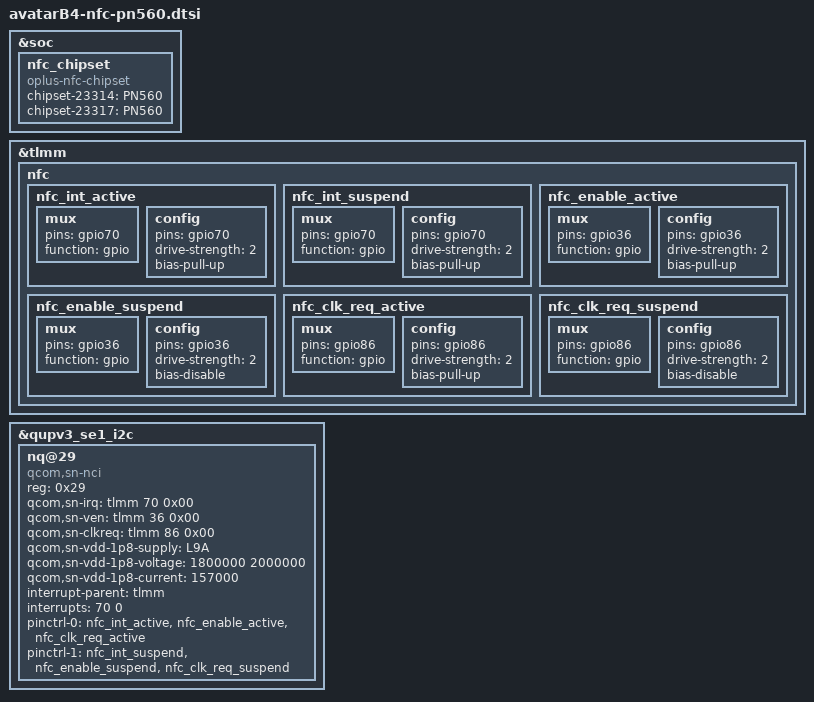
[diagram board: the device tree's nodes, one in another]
&soc {
	//add for nfc_chipset
	nfc_chipset {
		compatible = "oplus-nfc-chipset";
		chipset-23314 = "PN560";
		chipset-23317 = "PN560";
	};
};

&tlmm {
	nfc {
		nfc_int_active: nfc_int_active {
			/* active state */
			mux {
				/* GPIO 70 NFC Read Interrupt */
				pins = "gpio70";
				function = "gpio";
			};

			config {
				pins = "gpio70";
				drive-strength = <2>; /* 2 MA */
				bias-pull-up;
			};
		};

		nfc_int_suspend: nfc_int_suspend {
			/* sleep state */
			mux {
				/* GPIO 70 NFC Read Interrupt */
				pins = "gpio70";
				function = "gpio";
			};

			config {
				pins = "gpio70";
				drive-strength = <2>; /* 2 MA */
				bias-pull-up;
			};
		};

		nfc_enable_active: nfc_enable_active {
			/* active state */
			mux {
				/* 36: Enable */
				pins = "gpio36";
				function = "gpio";
			};

			config {
				pins = "gpio36";
				drive-strength = <2>; /* 2 MA */
				bias-pull-up;
			};
		};

		nfc_enable_suspend: nfc_enable_suspend {
			/* sleep state */
			mux {
				/* 36: Enable */
				pins = "gpio36";
				function = "gpio";
			};

			config {
				pins = "gpio36";
				drive-strength = <2>; /* 2 MA */
				bias-disable;
			};
		};

		nfc_clk_req_active: nfc_clk_req_active {
			/* active state */
			mux {
				/* GPIO 86: NFC CLOCK REQUEST */
				pins = "gpio86";
				function = "gpio";
			};

			config {
				pins = "gpio86";
				drive-strength = <2>; /* 2 MA */
				bias-pull-up;
			};
		};

		nfc_clk_req_suspend: nfc_clk_req_suspend {
			/* sleep state */
			mux {
				/* GPIO 86: NFC CLOCK REQUEST */
				pins = "gpio86";
				function = "gpio";
			};

			config {
				pins = "gpio86";
				drive-strength = <2>; /* 2 MA */
				bias-disable;
			};
		};
	};
}; //tlmm

&qupv3_se1_i2c {
	status = "ok";
	#address-cells = <1>;
	#size-cells = <0>;
	nq@29 {
		compatible = "qcom,sn-nci";
		reg = <0x29>;
		qcom,sn-irq = <&tlmm 70 0x00>;
		qcom,sn-ven = <&tlmm 36 0x00>;
		qcom,sn-clkreq = <&tlmm 86 0x00>;
		qcom,sn-vdd-1p8-supply = <&L9A>;
		qcom,sn-vdd-1p8-voltage = <1800000 2000000>;
		qcom,sn-vdd-1p8-current = <157000>;
		interrupt-parent = <&tlmm>;
		interrupts = <70 0>;
		interrupt-names = "nfc_irq";
		pinctrl-names = "nfc_active", "nfc_suspend";
		pinctrl-0 = <&nfc_int_active &nfc_enable_active
				&nfc_clk_req_active>;
		pinctrl-1 = <&nfc_int_suspend &nfc_enable_suspend
				&nfc_clk_req_suspend>;
	};
};
